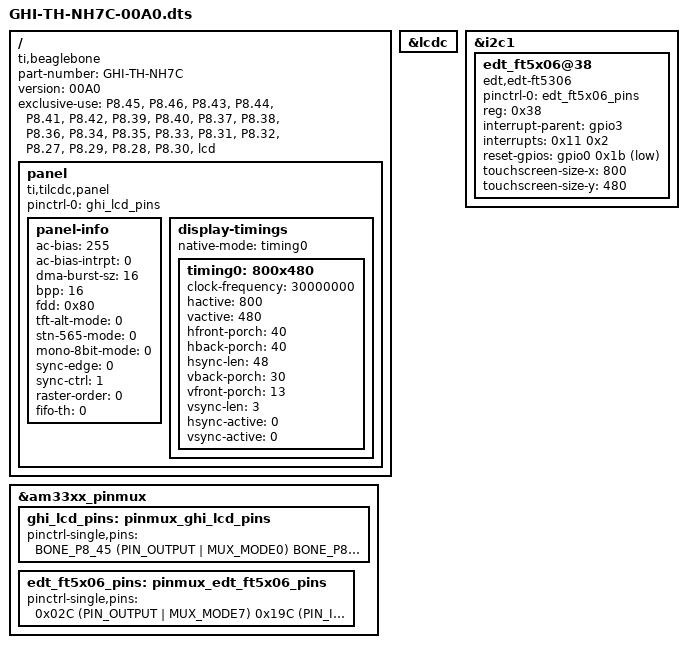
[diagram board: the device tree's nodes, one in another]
/*
 * Copyright (C) 2012 Texas Instruments Incorporated - http://www.ti.com/
 * Copyright (C) 2016 GHI Electronics, LLC - http://www.ghielectronics.com/ 
 *
 * This program is free software; you can redistribute it and/or modify
 * it under the terms of the GNU General Public License version 2 as
 * published by the Free Software Foundation.
 */
 
/dts-v1/;
/plugin/;

#include <dt-bindings/board/am335x-bbw-bbb-base.h>
#include <dt-bindings/gpio/gpio.h>
#include <dt-bindings/pinctrl/am33xx.h>

/ {
	compatible = "ti,beaglebone", "ti,beaglebone-black", "ti,beaglebone-green";

	part-number = "GHI-TH-NH7C";
	version = "00A0";

	exclusive-use =
		"P8.45", /* lcd: lcd_data0 */
		"P8.46", /* lcd: lcd_data1 */
		"P8.43", /* lcd: lcd_data2 */
		"P8.44", /* lcd: lcd_data3 */
		"P8.41", /* lcd: lcd_data4 */
		"P8.42", /* lcd: lcd_data5 */
		"P8.39", /* lcd: lcd_data6 */
		"P8.40", /* lcd: lcd_data7 */
		"P8.37", /* lcd: lcd_data8 */
		"P8.38", /* lcd: lcd_data9 */
		"P8.36", /* lcd: lcd_data10 */
		"P8.34", /* lcd: lcd_data11 */
		"P8.35", /* lcd: lcd_data12 */
		"P8.33", /* lcd: lcd_data13 */
		"P8.31", /* lcd: lcd_data14 */
		"P8.32", /* lcd: lcd_data15 */
		"P8.27", /* lcd: lcd_vsync */
		"P8.29", /* lcd: lcd_hsync */
		"P8.28", /* lcd: lcd_pclk */
		"P8.30", /* lcd: lcd_ac_bias_en */		
		"lcd";

	fragment@0 {
		target = <&am33xx_pinmux>;
		
		__overlay__ {
			ghi_lcd_pins: pinmux_ghi_lcd_pins {
				pinctrl-single,pins = <
					BONE_P8_45 (PIN_OUTPUT | MUX_MODE0) /* lcd_data0.lcd_data0 */
					BONE_P8_46 (PIN_OUTPUT | MUX_MODE0) /* lcd_data1.lcd_data1 */
					BONE_P8_43 (PIN_OUTPUT | MUX_MODE0) /* lcd_data2.lcd_data2 */
					BONE_P8_44 (PIN_OUTPUT | MUX_MODE0) /* lcd_data3.lcd_data3 */
					BONE_P8_41 (PIN_OUTPUT | MUX_MODE0) /* lcd_data4.lcd_data4 */
					BONE_P8_42 (PIN_OUTPUT | MUX_MODE0) /* lcd_data5.lcd_data5 */
					BONE_P8_39 (PIN_OUTPUT | MUX_MODE0) /* lcd_data6.lcd_data6 */
					BONE_P8_40 (PIN_OUTPUT | MUX_MODE0) /* lcd_data7.lcd_data7 */
					BONE_P8_37 (PIN_OUTPUT | MUX_MODE0) /* lcd_data8.lcd_data8 */
					BONE_P8_38 (PIN_OUTPUT | MUX_MODE0) /* lcd_data9.lcd_data9 */
					BONE_P8_36 (PIN_OUTPUT | MUX_MODE0) /* lcd_data10.lcd_data10 */
					BONE_P8_34 (PIN_OUTPUT | MUX_MODE0) /* lcd_data11.lcd_data11 */
					BONE_P8_35 (PIN_OUTPUT | MUX_MODE0) /* lcd_data12.lcd_data12 */
					BONE_P8_33 (PIN_OUTPUT | MUX_MODE0) /* lcd_data13.lcd_data13 */
					BONE_P8_31 (PIN_OUTPUT | MUX_MODE0) /* lcd_data14.lcd_data14 */
					BONE_P8_32 (PIN_OUTPUT | MUX_MODE0) /* lcd_data15.lcd_data15 */
					BONE_P8_27 (PIN_OUTPUT | MUX_MODE0) /* lcd_vsync.lcd_vsync */
					BONE_P8_29 (PIN_OUTPUT | MUX_MODE0) /* lcd_hsync.lcd_hsync */
					BONE_P8_28 (PIN_OUTPUT | MUX_MODE0) /* lcd_pclk.lcd_pclk */
					BONE_P8_30 (PIN_OUTPUT | MUX_MODE0) /* lcd_ac_bias_en.lcd_ac_bias_en */
				>;
			};

			edt_ft5x06_pins:pinmux_edt_ft5x06_pins  {
			   pinctrl-single,pins = <0x02C (PIN_OUTPUT | MUX_MODE7) 0x19C (PIN_INPUT | MUX_MODE7)>;
			};
		};
	};

	fragment@1 {
		target = <&lcdc>;
		
		__overlay__ {
			status = "okay";
		};
	};

	fragment@2 {
		target-path="/";
		
		__overlay__ {			
			#address-cells = <1>;
			#size-cells = <1>;

			panel {
				status = "okay";
				compatible = "ti,tilcdc,panel";
				pinctrl-names = "default";
				pinctrl-0 = <&ghi_lcd_pins>;
				
				panel-info {
					ac-bias           = <255>;
					ac-bias-intrpt    = <0>;
					dma-burst-sz      = <16>;
					bpp               = <16>;
					fdd               = <0x80>;
					tft-alt-mode      = <0>;
					stn-565-mode      = <0>;
					mono-8bit-mode    = <0>;
					sync-edge         = <0>;
					sync-ctrl         = <1>;
					raster-order      = <0>;
					fifo-th           = <0>;
				};
				
				display-timings {
					native-mode = <&timing0>;
					
					timing0: 800x480 {
						clock-frequency = <30000000>;
						hactive = <800>;
						vactive = <480>;
						hfront-porch = <40>;
						hback-porch = <40>;
						hsync-len = <48>;
						vback-porch = <30>;
						vfront-porch = <13>;
						vsync-len = <3>;
						hsync-active = <0>;
						vsync-active  = <0>;
					};
				};
			};
		};
	};
	
	fragment@3 {
		target = <&i2c1>;  
		
		__overlay__ {
			#address-cells = <1>;
			#size-cells = <0>;

			edt_ft5x06@38 {
				status =  "okay";
				compatible = "edt,edt-ft5306","edt,edt-ft5406","edt,edt-ft5206","edt,edt-ft5x06";
				pinctrl-names="default";
				pinctrl-0=<&edt_ft5x06_pins>;
				reg = <0x38>;
				interrupt-parent = <&gpio3>;
				interrupts = <0x11 0x2>;                      
				reset-gpios = <&gpio0 0x1b 1>;
				touchscreen-size-x = <800>;
				touchscreen-size-y = <480>;
			};
		};
	};
};
